AUTOSAR XML (schema 00047)
package /RSID
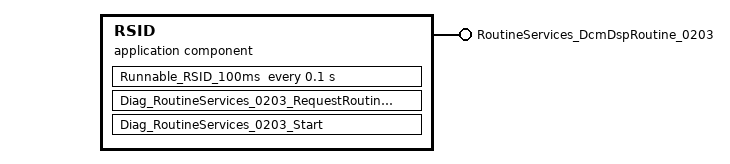
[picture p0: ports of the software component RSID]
  application sw component type RSID
    provide port RoutineServices_DcmDspRoutine_0203: provided-interface=RoutineServices_DcmDspRoutine_0203
    behavior SwcInternalBehavior_0
      timing event TE_Runnable_RSID_100ms: start-on-event=Runnable_RSID_100ms, period=0.1
      operation invoked event OIE_RoutineServices_0203_RequestRoutineResults: start-on-event=Diag_RoutineServices_0203_RequestRoutineResults, operation=RoutineServices_DcmDspRoutine_0203.RequestResults
      operation invoked event OIE_RoutineServices_0203_Start: start-on-event=Diag_RoutineServices_0203_Start, operation=RoutineServices_DcmDspRoutine_0203.Start
      runnable Runnable_RSID_100ms
      runnable Diag_RoutineServices_0203_RequestRoutineResults: symbol=Runnable_0203_RequestRoutineResults
      runnable Diag_RoutineServices_0203_Start: symbol=Runnable_0203_Start
